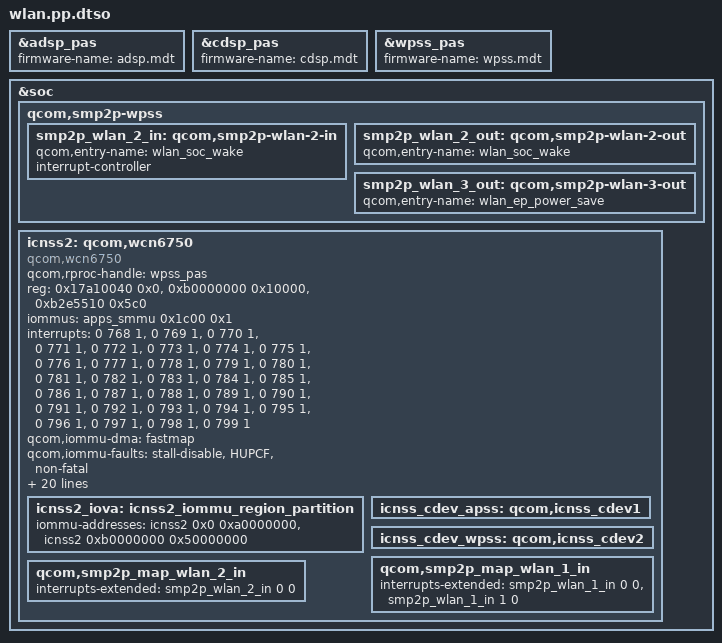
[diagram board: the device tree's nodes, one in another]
/dts-v1/; /plugin/;
&adsp_pas {
 firmware-name = "adsp.mdt";
};
&cdsp_pas {
 firmware-name = "cdsp.mdt";
};
&wpss_pas {
 firmware-name = "wpss.mdt";
};
&soc {
 qcom,smp2p-wpss {
  smp2p_wlan_2_in: qcom,smp2p-wlan-2-in {
   qcom,entry-name = "wlan_soc_wake";
   interrupt-controller;
   #interrupt-cells = <2>;
  };
  smp2p_wlan_2_out: qcom,smp2p-wlan-2-out {
   qcom,entry-name = "wlan_soc_wake";
   #qcom,smem-state-cells = <1>;
  };
  smp2p_wlan_3_out: qcom,smp2p-wlan-3-out {
   qcom,entry-name = "wlan_ep_power_save";
   #qcom,smem-state-cells = <1>;
  };
 };
 icnss2: qcom,wcn6750 {
  compatible = "qcom,wcn6750";
  qcom,rproc-handle = <&wpss_pas>;
  reg = <0x17a10040 0x0>,
        <0xb0000000 0x10000>,
        <0xb2e5510 0x5c0>;
  reg-names = "msi_addr", "smmu_iova_ipa", "tcs_cmd";
  iommus = <&apps_smmu 0x1c00 0x1>;
  interrupts = <0 768 1>,
        <0 769 1>,
        <0 770 1>,
        <0 771 1>,
        <0 772 1>,
        <0 773 1>,
        <0 774 1>,
        <0 775 1>,
        <0 776 1>,
        <0 777 1>,
        <0 778 1>,
        <0 779 1>,
        <0 780 1>,
        <0 781 1>,
        <0 782 1>,
        <0 783 1>,
        <0 784 1>,
        <0 785 1>,
        <0 786 1>,
        <0 787 1>,
        <0 788 1>,
        <0 789 1>,
        <0 790 1>,
        <0 791 1>,
        <0 792 1>,
        <0 793 1>,
        <0 794 1>,
        <0 795 1>,
        <0 796 1>,
        <0 797 1>,
        <0 798 1>,
        <0 799 1>;
  qcom,iommu-dma = "fastmap";
  qcom,iommu-faults = "stall-disable", "HUPCF", "non-fatal";
  memory-region = <&icnss2_iova>;
  qcom,iommu-geometry = <0xa0000000 0x10010000>;
  qcom,wlan-msa-fixed-region = <&wlan_fw_mem>;
  qcom,cmd_db_name = "smpb7";
  cnss-daemon-support;
  dma-coherent;
  qcom,fw-prefix;
  vdd-cx-mx-supply = <&S7B>;
  qcom,vdd-cx-mx-config = <824000 1120000 0 0 1>;
  vdd-1.8-xo-supply = <&S1B>;
  qcom,vdd-1.8-xo-config = <1872000 2040000 0 0 0>;
  vdd-1.3-rfa-supply = <&S8B>;
  qcom,vdd-1.3-rfa-config = <1256000 1500000 0 0 0>;
  qcom,smem-states = <&smp2p_wlan_1_out 0>,
       <&smp2p_wlan_2_out 0>,
       <&smp2p_wlan_3_out 0>;
  qcom,smem-state-names = "wlan-smp2p-out",
     "wlan-soc-wake-smp2p-out",
     "wlan-ep-powersave-smp2p-out";
  icnss2_iova: icnss2_iommu_region_partition {
   iommu-addresses = <&icnss2 0x0 0xa0000000>,
       <&icnss2 0xb0000000 0x50000000>;
  };
  icnss_cdev_apss: qcom,icnss_cdev1 {
   #cooling-cells = <2>;
  };
  icnss_cdev_wpss: qcom,icnss_cdev2 {
   #cooling-cells = <2>;
  };
  qcom,smp2p_map_wlan_1_in {
   interrupts-extended = <&smp2p_wlan_1_in 0 0>,
           <&smp2p_wlan_1_in 1 0>;
   interrupt-names = "qcom,smp2p-force-fatal-error",
       "qcom,smp2p-early-crash-ind";
  };
  qcom,smp2p_map_wlan_2_in {
   interrupts-extended = <&smp2p_wlan_2_in 0 0>;
   interrupt-names = "qcom,smp2p-soc-wake-ack";
  };
 };
};
&wpss_pas {
 firmware-name = "wpss.mdt";
};
&icnss2 {
 qcom,wlan;
 qcom,wlan-legacy-ipc-transport;
};
